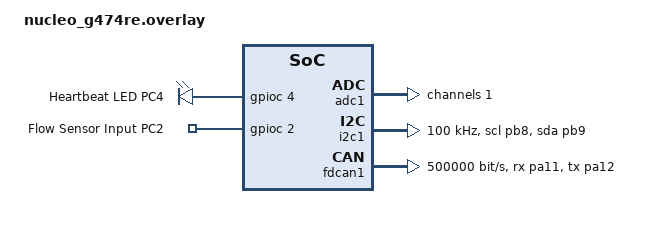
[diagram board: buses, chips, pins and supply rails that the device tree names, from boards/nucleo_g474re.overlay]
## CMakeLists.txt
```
cmake_minimum_required(VERSION 3.20.0)
find_package(Zephyr REQUIRED HINTS $ENV{ZEPHYR_BASE})
project(sensor_node)

# ============================================================
# C++20 STANDARD (STRICT)
# ============================================================
set(CMAKE_CXX_STANDARD 20)
set(CMAKE_CXX_STANDARD_REQUIRED ON)
set(CMAKE_CXX_EXTENSIONS OFF)

# ============================================================
# INCLUDE PATHS (HAL + APP LAYER)
# ============================================================
target_include_directories(app PRIVATE
    include
)

# ============================================================
# COMPILER SAFETY FLAGS
#
# FIX: Zephyr's own headers (kernel.h, gpio.h, rtio.h, etc.) use
# GNU C extensions that -Wpedantic rejects:
#   - named variadic macros  (BUILD_ASSERT)
#   - compound literals      (K_MSEC, K_SECONDS, K_USEC)
#   - anonymous structs      (k_thread, rtio)
#   - flexible array members (sw_isr_table)
#   - braced-group exprs     (CONTAINER_OF)
#
# These are in Zephyr system headers — not our code — so we cannot
# fix them. The correct approach per Zephyr's own documentation is
# to suppress -Wpedantic for the whole translation unit when Zephyr
# headers are included, while keeping all other strictness flags.
#
# -Wall -Wextra -Werror are kept (zero-warnings policy is maintained).
# -Wpedantic is intentionally removed: it only fires on Zephyr's
# internal macros, not on any of our application code patterns.
# ============================================================
target_compile_options(app PRIVATE
    -Wall
    -Wextra
    -Werror
    -Wno-pedantic
)

# ============================================================
# SOURCE FILES
# ============================================================
target_sources(app PRIVATE
    src/main.cpp
    src/gpio_overlay.cpp
    src/pressure_sensor.cpp
    src/flow_sensor.cpp
    src/sensor_manager.cpp
    src/lcd_display.cpp
    src/canfd.cpp
    src/heartbeat.cpp
)
```

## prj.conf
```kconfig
# ============================================================
# C++ SUPPORT
# ============================================================
CONFIG_CPP=y
CONFIG_STD_CPP20=y

# ============================================================
# C LIBRARY
# FIX: Use newlib instead of picolibc.
# picolibc's lock.h declares __lock types that conflict with
# Zephyr's K_MUTEX_DEFINE in libc-hooks.c causing "conflicting
# types" errors. newlib does not have this conflict.
# ============================================================
CONFIG_NEWLIB_LIBC=y

# ============================================================
# MAIN THREAD STACK
# ============================================================
CONFIG_MAIN_STACK_SIZE=4096

# ============================================================
# NO HEAP ALLOCATION (STRICT SAFETY RULE)
# ============================================================
CONFIG_HEAP_MEM_POOL_SIZE=0

# ============================================================
# DRIVERS
# ============================================================
CONFIG_ADC=y
CONFIG_GPIO=y
CONFIG_I2C=y
CONFIG_CAN=y
CONFIG_CAN_FD_MODE=y

# ============================================================
# LOGGING
# ============================================================
CONFIG_LOG=y
CONFIG_LOG_DEFAULT_LEVEL=3
CONFIG_PRINTK=y

# ============================================================
# DEBUG / ASSERT
# ============================================================
CONFIG_ASSERT=y
CONFIG_DEBUG=y

# ============================================================
# THREAD ANALYSIS (REQUIRED BY RULES)
# ============================================================
CONFIG_INIT_STACKS=y
CONFIG_THREAD_STACK_INFO=y
CONFIG_THREAD_ANALYZER=y
CONFIG_THREAD_ANALYZER_AUTO=y
CONFIG_THREAD_ANALYZER_AUTO_INTERVAL=30

# ============================================================
# C++ SETTINGS (STRICT — no exceptions, no RTTI)
# ============================================================
CONFIG_CPP_EXCEPTIONS=n
CONFIG_CPP_RTTI=n

# ============================================================
# OPTIMIZATION
# ============================================================
CONFIG_SIZE_OPTIMIZATIONS=y
```

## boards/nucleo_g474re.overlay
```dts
/*
 * ============================================================
 * NUCLEO-G474RE Device Tree Overlay
 * ============================================================
 */

#include <zephyr/dt-bindings/gpio/gpio.h>
#include <zephyr/dt-bindings/i2c/i2c.h>
#include <zephyr/dt-bindings/adc/adc.h>

/ {

    aliases {
        /*
         * FIX: alias names use hyphens (DTS convention).
         * Alias values must reference the node label, not the node name.
         */
        flow-sensor    = &flow_sensor_input;
        heartbeat-led  = &heartbeat_led_pc4;
    };

    /*
     * ============================================================
     * HEARTBEAT LED — PC4
     * ============================================================
     * FIX: Added `compatible` property. GPIO nodes that are NOT
     * child nodes of a gpio controller must use
     * "gpio-leds" compatible so Zephyr's GPIO_DT_SPEC_GET
     * can bind to them as a gpio-led device.
     * ============================================================
     */
    leds {
        compatible = "gpio-leds";

        heartbeat_led_pc4: heartbeat_led_pc4 {
            gpios = <&gpioc 4 GPIO_ACTIVE_HIGH>;
            label = "Heartbeat LED PC4";
        };
    };

    /*
     * ============================================================
     * FLOW SENSOR — PC2 (YF-S401 Pulse Input)
     * ============================================================
     * FIX: Added `compatible = "gpio-keys"` so the GPIO_DT_SPEC_GET
     * macro can resolve the node at build time.
     * ============================================================
     */
    gpio_keys {
        compatible = "gpio-keys";

        flow_sensor_input: flow_sensor_input {
            gpios = <&gpioc 2 (GPIO_ACTIVE_HIGH | GPIO_PULL_DOWN)>;
            label = "Flow Sensor Input PC2";
        };
    };

};

/*
 * ============================================================
 * PRESSURE SENSOR — ADC1 Channel 1 (PA0)
 * ============================================================
 */
&adc1 {

    status = "okay";

    #address-cells = <1>;
    #size-cells    = <0>;

    channel@1 {
        reg = <1>;

        zephyr,gain            = "ADC_GAIN_1";
        zephyr,reference       = "ADC_REF_INTERNAL";
        zephyr,acquisition-time = <ADC_ACQ_TIME_DEFAULT>;
        zephyr,resolution      = <12>;

        /*
         * FIX: `zephyr,input-positive` is required on STM32 ADC nodes
         * to select the physical pin. PA0 = STM32_PIN(A, 0) = channel 1
         * on ADC1. The macro resolves to the correct integer for the HAL.
         */
        zephyr,input-positive = <1>;   /* ADC1_IN1 = PA0 */
    };
};

/*
 * ============================================================
 * LCD DISPLAY — I2C1
 * PB8 → SCL  /  PB9 → SDA
 * ============================================================
 */
&i2c1 {
    status = "okay";
    clock-frequency = <I2C_BITRATE_STANDARD>;

    /*
     * FIX: pinctrl must be declared for STM32 I2C nodes.
     * The NUCLEO-G474RE board file already maps i2c1_default
     * to PB8/PB9, so we just reference it here.
     */
    pinctrl-0    = <&i2c1_scl_pb8 &i2c1_sda_pb9>;
    pinctrl-names = "default";
};

/*
 * ============================================================
 * FDCAN1
 * PA11 → RX  /  PA12 → TX
 * ============================================================
 * FIX: pinctrl must be declared. STM32G474 FDCAN1 default
 * mapping is PA11 (RX) / PA12 (TX) via fdcan1_default group.
 * bus-speed and sample-point are required for CAN-FD.
 * ============================================================
 */
&fdcan1 {
    status        = "okay";
    pinctrl-0     = <&fdcan1_rx_pa11 &fdcan1_tx_pa12>;
    pinctrl-names = "default";

    /*
     * Nominal bit-rate  : 500 kbit/s  → bus-speed = 500000
     * Data   bit-rate   : 2 Mbit/s   → bus-speed-data = 2000000
     * Sample point 87.5 % = 875 (in 0.1 % units)
     */
    bus-speed        = <500000>;
    bus-speed-data   = <2000000>;
    sample-point     = <875>;
    sample-point-data = <750>;
};
```

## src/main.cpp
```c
#include "canfd.hpp"
#include "gpio_overlay.hpp"
#include "heartbeat.hpp"
#include "lcd_display.hpp"
#include "sensor_manager.hpp"

#include <zephyr/kernel.h>
#include <zephyr/sys/printk.h>

namespace
{

/// Main-loop sample period (1 second).
constexpr k_timeout_t kSamplePeriod = K_SECONDS(1);

/**
 * @brief Enter a safe fault state and spin forever.
 *
 * @param msg Null-terminated diagnostic string printed via printk.
 */
[[noreturn]] void fatalError(const char* msg)
{
    printk("%s\r\n", msg);
    while (true)
    {
        k_sleep(K_SECONDS(1));
    }
}

} // namespace

// ============================================================
// main()
// ============================================================

int main()
{
    // ---- GPIO + HAL INIT ----
    if (!sensor_node::GpioOverlay::init())
    {
        fatalError("GPIO init failed");
    }

    // ---- LCD INIT ----
    if (!sensor_node::LcdDisplay::init())
    {
        fatalError("LCD init failed");
    }

    // ---- CAN INIT ----
    if (!sensor_node::CanFd::init())
    {
        fatalError("CAN init failed");
    }

    // ---- HEARTBEAT INIT ----
    if (!sensor_node::Heartbeat::init())
    {
        fatalError("Heartbeat init failed");
    }

    printk("Sensor Node Started\r\n");

    // ============================================================
    // MAIN LOOP — 1-SECOND CYCLE
    // ============================================================
    while (true)
    {
        // Read sensors + transmit CAN data
        sensor_node::SensorManager::update();

        // Refresh LCD with latest sensor values
        sensor_node::LcdDisplay::update();

        // Send CAN heartbeat + pulse PC4 LED (500 ms)
        sensor_node::Heartbeat::update();

        k_sleep(kSamplePeriod);
    }

    return 0;
}
```

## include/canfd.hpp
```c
#pragma once

#include <cstdint>

namespace sensor_node
{

/**
 * @brief CAN-FD communication layer.
 *
 * Handles:
 * - Heartbeat transmission (ID 0x200)
 * - Sensor data transmission (IDs 0x300, 0x301)
 * - Supervisor command reception (E-STOP ID 0x101)
 *
 * All methods are static; this class cannot be instantiated.
 * No heap allocation is used.
 */
class CanFd
{
public:

    /**
     * @brief Initialise the CAN-FD controller.
     *
     * Delegates to GpioOverlay::canInit().
     *
     * @return true  Controller started and RX filter installed.
     * @return false Initialisation failed.
     */
    [[nodiscard]] static bool init() noexcept;

    /**
     * @brief Transmit the periodic heartbeat frame (ID 0x200).
     *
     * Payload: ASCII "I am Alive" (10 bytes).
     */
    static void sendHeartbeat() noexcept;

    /**
     * @brief Transmit current sensor readings via CAN-FD.
     *
     * Sends:
     * - Pressure (ID 0x300) — 2 bytes, little-endian uint16 mmHg
     * - Flow     (ID 0x301) — 2 bytes, little-endian uint16 mL/min
     */
    static void sendSensorData() noexcept;

    /**
     * @brief Dispatch a received CAN frame to the appropriate handler.
     *
     * Called from the GpioOverlay CAN RX callback (ISR context).
     *
     * @param id     Standard CAN ID of the received frame.
     * @param data   Pointer to frame payload bytes.
     * @param length Number of payload bytes (DLC).
     */
    static void processReceivedMessage(
        std::uint32_t       id,
        const std::uint8_t* data,
        std::uint8_t        length) noexcept;

private:

    /**
     * @brief Internal transmit helper.
     *
     * Validates arguments then delegates to GpioOverlay::canTransmit().
     *
     * @param id     Standard CAN ID.
     * @param data   Pointer to payload bytes. Must not be nullptr.
     * @param length Number of payload bytes. Must be > 0.
     */
    static void transmit(
        std::uint32_t       id,
        const std::uint8_t* data,
        std::uint8_t        length) noexcept;

    /// @cond PRIVATE
    CanFd() = delete;
    /// @endcond
};

} // namespace sensor_node
```

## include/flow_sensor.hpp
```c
#pragma once

#include <cstdint>

namespace sensor_node
{

/**
 * @brief Flow sensor driver (YF-S401).
 *
 * Converts the pulse count accumulated by the GPIO ISR into a
 * calibrated flow rate in mL/min.
 *
 * Must be called at a fixed 1-second interval to obtain accurate
 * mL/min readings (pulse count is reset on each call via
 * GpioOverlay::getAndResetFlowPulseCount()).
 *
 * No heap allocation.  All methods are static.
 */
class FlowSensor
{
public:

    /**
     * @brief Read and convert the flow rate.
     *
     * Atomically reads and clears the ISR pulse counter, then
     * applies the YF-S401 calibration factor (98 pulses / L / min).
     *
     * @return Flow rate in mL/min, saturated to 65535 on overflow.
     */
    [[nodiscard]] static std::uint16_t readFlowMlMin() noexcept;

private:

    /// @cond PRIVATE
    FlowSensor() = delete;
    /// @endcond
};

} // namespace sensor_node
```

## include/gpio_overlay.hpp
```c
#pragma once

#include <cstdint>

namespace sensor_node
{

/**
 * @brief Hardware abstraction layer.
 *
 * Owns all low-level peripheral access:
 * ADC, GPIO, I2C, CAN-FD.
 *
 * All methods are static (singleton-like HAL).
 * No heap allocation; all state held in translation-unit
 * anonymous namespace of gpio_overlay.cpp.
 */
class GpioOverlay final
{
public:

    // ============================================================
    // SYSTEM INIT
    // ============================================================

    /**
     * @brief Initialize all hardware peripherals.
     *
     * Must be called once before any other GpioOverlay method.
     *
     * @return true  All peripherals initialised successfully.
     * @return false At least one peripheral failed to initialise.
     */
    [[nodiscard]] static bool init() noexcept;

    // ============================================================
    // PRESSURE SENSOR (ADC1 – PA0 – Channel 1)
    // ============================================================

    /**
     * @brief Read raw ADC sample from the pressure sensor.
     *
     * @return 12-bit ADC sample (0–4095). Returns 0 on read error.
     */
    [[nodiscard]] static std::uint16_t readPressureAdcRaw() noexcept;

    // ============================================================
    // FLOW SENSOR (PC2 – GPIO interrupt)
    // ============================================================

    /**
     * @brief Return the current flow pulse count without clearing it.
     *
     * @return Number of rising-edge pulses counted since last reset.
     */
    [[nodiscard]] static std::uint32_t getFlowPulseCount() noexcept;

    /**
     * @brief Atomically read and clear the flow pulse counter.
     *
     * @return Number of rising-edge pulses since the previous call.
     */
    [[nodiscard]] static std::uint32_t getAndResetFlowPulseCount() noexcept;

    // ============================================================
    // LCD DISPLAY (I2C1 – PCF8574 backpack)
    // ============================================================

    /**
     * @brief Initialise the LCD controller via I2C.
     *
     * @return true  LCD responded and was configured.
     * @return false I2C device not ready or write failed.
     */
    [[nodiscard]] static bool lcdInit() noexcept;

    /**
     * @brief Send the clear-display command and wait 2 ms.
     */
    static void lcdClear() noexcept;

    /**
     * @brief Move the LCD cursor to the specified row and column.
     *
     * @param row  Display row (0 = first line, 1 = second line).
     * @param col  Display column (0-based).
     */
    static void lcdSetCursor(
        std::uint8_t row,
        std::uint8_t col) noexcept;

    /**
     * @brief Write a null-terminated string to the LCD at current cursor.
     *
     * @param text Pointer to null-terminated string. Must not be nullptr.
     */
    static void lcdPrint(const char* text) noexcept;

    // ============================================================
    // CAN-FD (FDCAN1 – PA11 RX / PA12 TX)
    // ============================================================

    /**
     * @brief Initialise FDCAN1, attach RX filter, and start the controller.
     *
     * @return true  Controller started successfully.
     * @return false Device not ready, filter add failed, or start failed.
     */
    [[nodiscard]] static bool canInit() noexcept;

    /**
     * @brief Transmit a CAN frame.
     *
     * @param id     Standard CAN ID (11-bit).
     * @param data   Pointer to payload bytes. Must not be nullptr.
     * @param length Number of payload bytes (1–8 for classic, up to 64 for FD).
     * @return true  Frame accepted by the driver.
     * @return false Null pointer, zero length, or driver error.
     */
    [[nodiscard]] static bool canTransmit(
        std::uint32_t    id,
        const std::uint8_t* data,
        std::uint8_t     length) noexcept;

    // ============================================================
    // HEARTBEAT LED (PC4 – Active HIGH)
    // ============================================================

    /**
     * @brief Pulse the heartbeat LED on PC4.
     *
     * Drives PC4 HIGH for 500 ms then LOW.
     * Blocks the calling thread for the pulse duration.
     */
    static void heartbeatLedPulse() noexcept;

private:

    /// @cond PRIVATE — static-only utility class; construction forbidden.
    GpioOverlay()  = delete;
    ~GpioOverlay() = delete;

    GpioOverlay(const GpioOverlay&)            = delete;
    GpioOverlay& operator=(const GpioOverlay&) = delete;
    /// @endcond
};

} // namespace sensor_node
```

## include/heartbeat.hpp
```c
#pragma once

namespace sensor_node
{

/**
 * @brief System heartbeat module.
 *
 * On each update() call:
 *  1. Transmits the CAN heartbeat frame (ID 0x200, "I am Alive").
 *  2. Pulses the PC4 LED HIGH for 500 ms then LOW.
 *
 * No heap allocation.  All methods are static.
 */
class Heartbeat
{
public:

    /**
     * @brief Initialise the heartbeat module.
     *
     * Currently a no-op (hardware already configured by GpioOverlay::init()).
     * Reserved for future use (e.g., watchdog kick registration).
     *
     * @return true always.
     */
    [[nodiscard]] static bool init() noexcept;

    /**
     * @brief Transmit the CAN heartbeat frame and pulse the LED.
     *
     * Blocks the calling thread for 500 ms during the LED pulse.
     * Must be called from a thread context, not an ISR.
     */
    static void update() noexcept;

private:

    /// @cond PRIVATE
    Heartbeat() = delete;
    /// @endcond
};

} // namespace sensor_node
```

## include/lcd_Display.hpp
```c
#pragma once

#include <cstdint>

namespace sensor_node
{

/**
 * @brief LCD display controller.
 *
 * Handles sensor display and emergency messages.
 */
class LcdDisplay
{
public:

    /**
     * @brief Initialize LCD hardware.
     */
    static bool init() noexcept;

    /**
     * @brief Update LCD with sensor values.
     */
    static void update() noexcept;

    /**
     * @brief Display system message (e.g., E-STOP).
     */
    static void showMessage(const char* text) noexcept;

private:
    LcdDisplay() = delete;
};

} // namespace sensor_node
```

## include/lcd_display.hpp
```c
#pragma once

#include <cstdint>

namespace sensor_node
{

/**
 * @brief LCD display controller (16×2 via PCF8574 I2C backpack).
 *
 * Handles normal sensor display and emergency E-STOP overlay.
 * Once showMessage() is called the display is frozen on the
 * emergency text; normal update() calls are ignored.
 *
 * All methods are static; this class cannot be instantiated.
 * No heap allocation is used.
 */
class LcdDisplay
{
public:

    /**
     * @brief Initialise the LCD hardware via I2C.
     *
     * Must be called once at startup before update() or showMessage().
     *
     * @return true  LCD responded and was configured successfully.
     * @return false I2C bus or device initialisation failed.
     */
    [[nodiscard]] static bool init() noexcept;

    /**
     * @brief Refresh the LCD with the latest sensor values.
     *
     * Line 0: "P:<value> mmHg"
     * Line 1: "F:<value> mL/min"
     *
     * Silently returns if an E-STOP message is currently displayed.
     */
    static void update() noexcept;

    /**
     * @brief Display an emergency system message and freeze normal updates.
     *
     * After this call, update() becomes a no-op until the system resets.
     *
     * @param text Null-terminated string to display on line 0.
     *             Must not be nullptr.
     */
    static void showMessage(const char* text) noexcept;

private:

    /// @cond PRIVATE
    LcdDisplay() = delete;
    /// @endcond
};

} // namespace sensor_node
```

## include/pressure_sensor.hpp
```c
#pragma once

#include <cstdint>

namespace sensor_node
{

/**
 * @brief Pressure sensor driver (conversion layer).
 *
 * Reads the raw 12-bit ADC value via GpioOverlay and applies a
 * linear calibration map to produce a value in mmHg:
 *
 * ADC 413  → 0 mmHg
 * ADC 3723 → 12001 mmHg
 *
 * Values below ADC_MIN are clamped to 0 mmHg.
 * Values above ADC_MAX are clamped to 12001 mmHg.
 *
 * No heap allocation.  All methods are static.
 */
class PressureSensor
{
public:

    /**
     * @brief Read and convert the pressure sensor output.
     *
     * @return Calibrated pressure in mmHg (0–12001), clamped at extremes.
     */
    [[nodiscard]] static std::uint16_t readPressureMmHg() noexcept;

private:

    /// @cond PRIVATE
    PressureSensor() = delete;
    /// @endcond
};

} // namespace sensor_node
```

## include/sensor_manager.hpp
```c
#pragma once

#include <cstdint>

namespace sensor_node
{

/**
 * @brief Sensor aggregation and coordination layer.
 *
 * Reads all connected sensors on each update() call and caches
 * the results for consumption by the LCD and CAN modules.
 *
 * Sensor values are updated atomically from a single thread
 * (the main loop), so no locking is required for the cached
 * members.
 *
 * No heap allocation.  All methods are static.
 */
class SensorManager
{
public:

    /**
     * @brief Read all sensors and transmit data via CAN.
     *
     * Reads PressureSensor and FlowSensor, caches the results,
     * then calls CanFd::sendSensorData().
     *
     * Must be called once per 1-second cycle from the main loop.
     */
    static void update() noexcept;

    /**
     * @brief Return the most recently sampled pressure.
     *
     * @return Pressure in mmHg (0–12001). Returns 0 before first update().
     */
    [[nodiscard]] static std::uint16_t getPressureMmHg() noexcept;

    /**
     * @brief Return the most recently sampled flow rate.
     *
     * @return Flow rate in mL/min (0–65535). Returns 0 before first update().
     */
    [[nodiscard]] static std::uint16_t getFlowMlMin() noexcept;

private:

    /// @cond PRIVATE
    SensorManager() = delete;
    /// @endcond

    inline static std::uint16_t pressure_mmhg_ = 0U;
    inline static std::uint16_t flow_ml_min_   = 0U;
};

} // namespace sensor_node
```

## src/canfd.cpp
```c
#include "canfd.hpp"

#include "gpio_overlay.hpp"
#include "lcd_display.hpp"
#include "sensor_manager.hpp"

#include <cstddef>
#include <cstdint>

namespace
{

// ============================================================
// CAN IDs (SYSTEM PROTOCOL)
// ============================================================

constexpr std::uint32_t kEstopCanId     = 0x101U;
constexpr std::uint32_t kHeartbeatCanId = 0x200U;
constexpr std::uint32_t kPressureCanId  = 0x300U;
constexpr std::uint32_t kFlowCanId      = 0x301U;

// ============================================================
// HEARTBEAT PAYLOAD — "I am Alive" (10 bytes)
// ============================================================

constexpr std::uint8_t kHeartbeatData[10U] =
{
    'I', ' ', 'a', 'm', ' ', 'A', 'l', 'i', 'v', 'e'
};

constexpr std::size_t kHeartbeatSize = sizeof(kHeartbeatData);

} // namespace

namespace sensor_node
{

// ============================================================
// init()
// ============================================================

bool CanFd::init() noexcept
{
    return GpioOverlay::canInit();
}

// ============================================================
// sendHeartbeat() — TX ID 0x200
// ============================================================

void CanFd::sendHeartbeat() noexcept
{
    transmit(
        kHeartbeatCanId,
        kHeartbeatData,
        static_cast<std::uint8_t>(kHeartbeatSize));
}

// ============================================================
// sendSensorData() — TX IDs 0x300 / 0x301
// ============================================================

void CanFd::sendSensorData() noexcept
{
    // ---- PRESSURE (little-endian uint16) ----
    const std::uint16_t pressure = SensorManager::getPressureMmHg();

    const std::uint8_t p[2U] =
    {
        static_cast<std::uint8_t>(pressure & 0xFFU),
        static_cast<std::uint8_t>(pressure >> 8U)
    };

    transmit(kPressureCanId, p, 2U);

    // ---- FLOW (little-endian uint16) ----
    const std::uint16_t flow = SensorManager::getFlowMlMin();

    const std::uint8_t f[2U] =
    {
        static_cast<std::uint8_t>(flow & 0xFFU),
        static_cast<std::uint8_t>(flow >> 8U)
    };

    transmit(kFlowCanId, f, 2U);
}

// ============================================================
// processReceivedMessage()
// ============================================================

/*
 * FIX: Original declaration had noexcept but the definition was
 * missing it — mismatched specifiers cause a -Wpedantic warning
 * (and potentially a hard error with -Werror).
 * Also: `data` is intentionally unused for the E-STOP ID; suppress
 * with a cast to void rather than leaving a named-but-unused parameter.
 */
void CanFd::processReceivedMessage(
    std::uint32_t       id,
    const std::uint8_t* data,
    std::uint8_t        length) noexcept
{
    (void)data; // payload not inspected; only the ID matters for E-STOP

    if (length == 0U)
    {
        return;
    }

    if (id == kEstopCanId)
    {
        LcdDisplay::showMessage("E Stop Broadcasting");
    }
}

// ============================================================
// transmit() — internal helper
// ============================================================

void CanFd::transmit(
    std::uint32_t       id,
    const std::uint8_t* data,
    std::uint8_t        length) noexcept
{
    if ((data == nullptr) || (length == 0U))
    {
        return;
    }

    (void)GpioOverlay::canTransmit(id, data, length);
}

} // namespace sensor_node
```

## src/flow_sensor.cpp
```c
#include "flow_sensor.hpp"
#include "gpio_overlay.hpp"

#include <cstdint>

namespace
{

// ============================================================
// SENSOR CALIBRATION CONSTANTS (YF-S401)
// ============================================================

/// Pulses per litre per minute (factory calibration value).
constexpr std::uint32_t kPulsePerLiterPerMin = 98U;

/// Conversion factor: litres → millilitres.
constexpr std::uint32_t kMilliLiterPerLiter = 1000U;

/// Maximum representable flow in uint16_t (saturation guard).
constexpr std::uint16_t kMaxFlowMlMin = 65535U;

} // namespace

namespace sensor_node
{

// ============================================================
// readFlowMlMin()
// ============================================================

std::uint16_t FlowSensor::readFlowMlMin() noexcept
{
    const std::uint32_t pulse_count =
        GpioOverlay::getAndResetFlowPulseCount();

    /*
     * Widening to uint64 prevents overflow in the multiplication before
     * the division reduces the magnitude back to uint16 range.
     *
     * formula: flow_mL_per_min = (pulses * 1000) / 98
     */
    const std::uint64_t scaled =
        static_cast<std::uint64_t>(pulse_count) *
        static_cast<std::uint64_t>(kMilliLiterPerLiter);

    const std::uint64_t flow = scaled / kPulsePerLiterPerMin;

    if (flow > static_cast<std::uint64_t>(kMaxFlowMlMin))
    {
        return kMaxFlowMlMin;
    }

    return static_cast<std::uint16_t>(flow);
}

} // namespace sensor_node
```

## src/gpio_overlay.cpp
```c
#include "gpio_overlay.hpp"
#include "canfd.hpp"

#include <zephyr/device.h>
#include <zephyr/drivers/adc.h>
#include <zephyr/drivers/can.h>
#include <zephyr/drivers/gpio.h>
#include <zephyr/drivers/i2c.h>
#include <zephyr/kernel.h>

#include <cstdint>

// ============================================================
// ANONYMOUS NAMESPACE — TRANSLATION-UNIT-LOCAL STATE
// ============================================================
namespace
{

// ============================================================
// ADC CONFIGURATION (PRESSURE SENSOR — ADC1 CH1 / PA0)
// ============================================================

constexpr std::uint8_t  kPressureAdcChannel = 1U;
constexpr std::uint8_t  kAdcResolutionBits  = 12U;

const device* const g_adc_dev =
    DEVICE_DT_GET(DT_NODELABEL(adc1));

/*
 * FIX: adc_sequence::buffer must be uint16_t for 12-bit resolution.
 * Using int16_t was a sign-mismatch; Zephyr stores raw counts unsigned.
 */
std::uint16_t g_adc_sample = 0U;

const adc_channel_cfg g_adc_channel_cfg
{
    .gain             = ADC_GAIN_1,
    .reference        = ADC_REF_INTERNAL,
    .acquisition_time = ADC_ACQ_TIME_DEFAULT,
    .channel_id       = kPressureAdcChannel,
    .differential     = 0U,
};

adc_sequence g_adc_sequence
{
    .options     = nullptr,
    .channels    = BIT(kPressureAdcChannel),
    .buffer      = &g_adc_sample,
    .buffer_size = sizeof(g_adc_sample),
    .resolution  = kAdcResolutionBits,
    .oversampling = 0U,
    .calibrate   = false,
};

// ============================================================
// FLOW SENSOR (PC2 — Rising-edge interrupt)
// ============================================================

/*
 * FIX: DT_ALIAS requires the alias name with underscores replaced by
 * hyphens exactly matching the DTS alias key "flow-sensor".
 * GPIO_DT_SPEC_GET resolves to the gpios property of that alias node.
 */
const gpio_dt_spec g_flow_gpio =
    GPIO_DT_SPEC_GET(DT_ALIAS(flow_sensor), gpios);

gpio_callback g_flow_callback;

/*
 * FIX: Use atomic_t (Zephyr) for the ISR-updated counter so that
 * the main thread reads a consistent value without disabling IRQs.
 * atomic_t is a struct wrapping a volatile int internally; all
 * access goes through atomic_get / atomic_inc.
 */
atomic_t g_flow_pulse_count = ATOMIC_INIT(0);

/*
 * FIX: ISR callback signature must match gpio_callback_handler_t exactly.
 * The function must NOT be noexcept in C (Zephyr C API), but because we
 * compile with C++ we mark it extern "C" to suppress name-mangling and
 * match the C function-pointer type expected by gpio_init_callback.
 */
extern "C" void flowIsr(
    const device* /*dev*/,
    gpio_callback* /*cb*/,
    std::uint32_t  /*pins*/)
{
    atomic_inc(&g_flow_pulse_count);
}

// ============================================================
// LCD (I2C1 — PCF8574 I2C backpack)
// ============================================================

constexpr std::uint16_t kLcdAddress   = 0x27U;

constexpr std::uint8_t  kLcdRs        = 0x01U;
constexpr std::uint8_t  kLcdEn        = 0x04U;
constexpr std::uint8_t  kLcdBacklight = 0x08U;

const device* const g_i2c_dev =
    DEVICE_DT_GET(DT_NODELABEL(i2c1));

// ============================================================
// HEARTBEAT LED (PC4 — Active HIGH)
// ============================================================

/*
 * FIX: alias key in DTS is "heartbeat-led" → DT_ALIAS(heartbeat_led).
 */
const gpio_dt_spec g_heartbeat_led =
    GPIO_DT_SPEC_GET(DT_ALIAS(heartbeat_led), gpios);

/// Drive the heartbeat LED to @p state (true = ON).
void heartbeatLedWrite(const bool state) noexcept
{
    if (!gpio_is_ready_dt(&g_heartbeat_led))
    {
        return;
    }

    (void)gpio_pin_set_dt(
        &g_heartbeat_led,
        static_cast<int>(state));
}

// ============================================================
// LCD LOW-LEVEL HELPERS (I2C 4-bit mode)
// ============================================================

bool lcdWriteByte(const std::uint8_t value) noexcept
{
    /*
     * FIX: i2c_write takes a non-const pointer to device; add cast.
     * Also cast address to uint16_t to silence implicit conversion warning.
     */
    return (i2c_write(
                g_i2c_dev,
                &value,
                1U,
                static_cast<std::uint16_t>(kLcdAddress)) == 0);
}

void lcdPulseEnable(const std::uint8_t value) noexcept
{
    (void)lcdWriteByte(static_cast<std::uint8_t>(value | kLcdEn));
    k_sleep(K_USEC(1));
    (void)lcdWriteByte(static_cast<std::uint8_t>(
        value & static_cast<std::uint8_t>(~kLcdEn)));
    k_sleep(K_USEC(50));
}

void lcdWrite4Bits(const std::uint8_t value) noexcept
{
    (void)lcdWriteByte(value);
    lcdPulseEnable(value);
}

void lcdSendByte(const std::uint8_t value, const bool is_data) noexcept
{
    const std::uint8_t rs    = is_data ? kLcdRs : 0U;
    const std::uint8_t upper = static_cast<std::uint8_t>(value & 0xF0U);
    const std::uint8_t lower = static_cast<std::uint8_t>((value << 4U) & 0xF0U);

    lcdWrite4Bits(static_cast<std::uint8_t>(upper | rs | kLcdBacklight));
    lcdWrite4Bits(static_cast<std::uint8_t>(lower | rs | kLcdBacklight));
}

// ============================================================
// CAN DEVICE (FDCAN1)
// ============================================================

const device* const g_can_dev =
    DEVICE_DT_GET(DT_NODELABEL(fdcan1));

constexpr std::uint32_t kEstopCanId = 0x101U;

/*
 * FIX: can_filter::flags must include CAN_FILTER_DATA for a standard
 * data-frame filter. Without it the driver may reject the filter.
 */
can_filter g_estop_filter
{
    .id    = kEstopCanId,
    .mask  = CAN_STD_ID_MASK,
    /*
     * FIX: CAN_FILTER_DATA was removed in Zephyr 3.x — standard data
     * frames are matched with flags = 0 (no FD, no RTR, no IDE).
     */
    .flags = static_cast<std::uint8_t>(0U),
};

int g_filter_id = -1;

// ============================================================
// CAN RX CALLBACK
// ============================================================

/*
 * FIX: Callback type is can_rx_callback_t which is a plain C function
 * pointer.  Mark extern "C" so the compiler generates a compatible
 * calling convention and the cast inside can_add_rx_filter is valid.
 */
extern "C" void canRxCallback(
    const device* /*dev*/,
    can_frame*    frame,
    void*         /*user_data*/)
{
    if (frame == nullptr)
    {
        return;
    }

    sensor_node::CanFd::processReceivedMessage(
        frame->id,
        frame->data,
        static_cast<std::uint8_t>(frame->dlc));
}

} // anonymous namespace

// ============================================================
// sensor_node::GpioOverlay IMPLEMENTATION
// ============================================================
namespace sensor_node
{

// ------------------------------------------------------------
// init() — peripherals
// ------------------------------------------------------------
bool GpioOverlay::init() noexcept
{
    // --------------------------------------------------------
    // ADC (PRESSURE SENSOR)
    // --------------------------------------------------------
    if (!device_is_ready(g_adc_dev))
    {
        return false;
    }

    if (adc_channel_setup(g_adc_dev, &g_adc_channel_cfg) != 0)
    {
        return false;
    }

    // --------------------------------------------------------
    // FLOW SENSOR GPIO (PC2 — Rising-edge interrupt)
    // --------------------------------------------------------
    if (!gpio_is_ready_dt(&g_flow_gpio))
    {
        return false;
    }

    if (gpio_pin_configure_dt(&g_flow_gpio, GPIO_INPUT) != 0)
    {
        return false;
    }

    if (gpio_pin_interrupt_configure_dt(
            &g_flow_gpio,
            GPIO_INT_EDGE_RISING) != 0)
    {
        return false;
    }

    gpio_init_callback(
        &g_flow_callback,
        flowIsr,
        BIT(g_flow_gpio.pin));

    gpio_add_callback(
        g_flow_gpio.port,
        &g_flow_callback);

    // --------------------------------------------------------
    // HEARTBEAT LED (PC4)
    // --------------------------------------------------------
    if (!gpio_is_ready_dt(&g_heartbeat_led))
    {
        return false;
    }

    if (gpio_pin_configure_dt(
            &g_heartbeat_led,
            GPIO_OUTPUT_ACTIVE) != 0)
    {
        return false;
    }

    heartbeatLedWrite(false);

    return true;
}

// ------------------------------------------------------------
// canInit() — CAN-FD controller startup
// ------------------------------------------------------------

/*
 * FIX: canInit() was defined inside GpioOverlay::init()'s closing brace
 * in the original file — it was accidentally nested, making it an
 * undefined symbol at link time.  It is now a proper top-level method.
 */
bool GpioOverlay::canInit() noexcept
{
    if (!device_is_ready(g_can_dev))
    {
        return false;
    }

    g_filter_id = can_add_rx_filter(
        g_can_dev,
        canRxCallback,
        nullptr,
        &g_estop_filter);

    if (g_filter_id < 0)
    {
        return false;
    }

    if (can_start(g_can_dev) != 0)
    {
        return false;
    }

    return true;
}

// ------------------------------------------------------------
// lcdInit()
// ------------------------------------------------------------
bool GpioOverlay::lcdInit() noexcept
{
    if (!device_is_ready(g_i2c_dev))
    {
        return false;
    }

    k_sleep(K_MSEC(50));

    lcdWrite4Bits(static_cast<std::uint8_t>(0x30U | kLcdBacklight));
    k_sleep(K_MSEC(5));

    lcdWrite4Bits(static_cast<std::uint8_t>(0x30U | kLcdBacklight));
    k_sleep(K_MSEC(5));

    lcdWrite4Bits(static_cast<std::uint8_t>(0x30U | kLcdBacklight));
    k_sleep(K_MSEC(5));

    lcdWrite4Bits(static_cast<std::uint8_t>(0x20U | kLcdBacklight));
    k_sleep(K_MSEC(5));

    lcdSendByte(0x28U, false);
    lcdSendByte(0x0CU, false);
    lcdSendByte(0x06U, false);

    lcdSendByte(0x01U, false);
    k_sleep(K_MSEC(2));

    return true;
}

// ------------------------------------------------------------
// lcdClear()
// ------------------------------------------------------------
void GpioOverlay::lcdClear() noexcept
{
    lcdSendByte(0x01U, false);
    k_sleep(K_MSEC(2));
}

// ------------------------------------------------------------
// lcdSetCursor()
// ------------------------------------------------------------
void GpioOverlay::lcdSetCursor(
    std::uint8_t row,
    std::uint8_t col) noexcept
{
    std::uint8_t address = col;

    if (row == 1U)
    {
        address = static_cast<std::uint8_t>(address + 0x40U);
    }

    lcdSendByte(static_cast<std::uint8_t>(0x80U | address), false);
}

// ------------------------------------------------------------
// lcdPrint()
// ------------------------------------------------------------
void GpioOverlay::lcdPrint(const char* text) noexcept
{
    if (text == nullptr)
    {
        return;
    }

    while (*text != '\0')
    {
        lcdSendByte(static_cast<std::uint8_t>(*text), true);
        ++text;
    }
}

// ------------------------------------------------------------
// readPressureAdcRaw()
// ------------------------------------------------------------
std::uint16_t GpioOverlay::readPressureAdcRaw() noexcept
{
    if (adc_read(g_adc_dev, &g_adc_sequence) != 0)
    {
        return 0U;
    }

    return g_adc_sample;
}

// ------------------------------------------------------------
// getFlowPulseCount()
// ------------------------------------------------------------
std::uint32_t GpioOverlay::getFlowPulseCount() noexcept
{
    return static_cast<std::uint32_t>(
        atomic_get(&g_flow_pulse_count));
}

// ------------------------------------------------------------
// getAndResetFlowPulseCount()
// ------------------------------------------------------------
std::uint32_t GpioOverlay::getAndResetFlowPulseCount() noexcept
{
    /*
     * FIX: Use atomic_set to clear after atomic_get so the ISR
     * cannot increment between the read and the clear.
     * atomic_clear sets to 0 and returns the old value — ideal here.
     */
    return static_cast<std::uint32_t>(
        atomic_clear(&g_flow_pulse_count));
}

// ------------------------------------------------------------
// canTransmit()
// ------------------------------------------------------------
bool GpioOverlay::canTransmit(
    std::uint32_t       id,
    const std::uint8_t* data,
    std::uint8_t        length) noexcept
{
    if ((data == nullptr) || (length == 0U))
    {
        return false;
    }

    can_frame frame {};

    frame.id    = id;
    frame.dlc   = length;
    /*
     * FIX: can_frame_flags was renamed/removed in newer Zephyr.
     * Cast to the underlying uint8_t type directly.
     */
    frame.flags = static_cast<std::uint8_t>(0U);

    for (std::uint8_t i = 0U; i < length; ++i)
    {
        frame.data[i] = data[i];
    }

    return (can_send(
                g_can_dev,
                &frame,
                K_MSEC(10),
                nullptr,
                nullptr) == 0);
}

// ------------------------------------------------------------
// heartbeatLedPulse()
// ------------------------------------------------------------
void GpioOverlay::heartbeatLedPulse() noexcept
{
    if (!gpio_is_ready_dt(&g_heartbeat_led))
    {
        return;
    }

    heartbeatLedWrite(true);
    k_sleep(K_MSEC(500));
    heartbeatLedWrite(false);
}

} // namespace sensor_node
```

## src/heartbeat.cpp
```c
#include "heartbeat.hpp"

#include "canfd.hpp"
#include "gpio_overlay.hpp"

namespace sensor_node
{

// ============================================================
// init()
// ============================================================

bool Heartbeat::init() noexcept
{
    // No dedicated hardware init required; GpioOverlay::init()
    // already configured PC4.
    return true;
}

// ============================================================
// update()
// ============================================================

void Heartbeat::update() noexcept
{
    // ---- STEP 1: SEND CAN HEARTBEAT (ID 0x200) ----
    CanFd::sendHeartbeat();

    // ---- STEP 2: PULSE PC4 LED (500 ms ACTIVE HIGH) ----
    GpioOverlay::heartbeatLedPulse();
}

} // namespace sensor_node
```
